# R7FA6T2BD register map
Vendor: Renesas Electronics Corporation; Series: RA6; File version: 1.40.00
CPU: CM33 r0p4, little endian, MPU, FPU, VTOR, 4 interrupt priority bits, 96 interrupts
Registers are 32-bit, read-write, reset 0x0 unless marked. A register's access mark holds for its fields unless they carry their own. Offsets are from the block's base; [hi:lo] are bit positions; {n}, {i} and the like mark numbered series.

## GPT320 — General PWM 32-bit Timer 0
Base 0x40169000
Same registers: GPT321 0x40169100, GPT322 0x40169200, GPT323 0x40169300
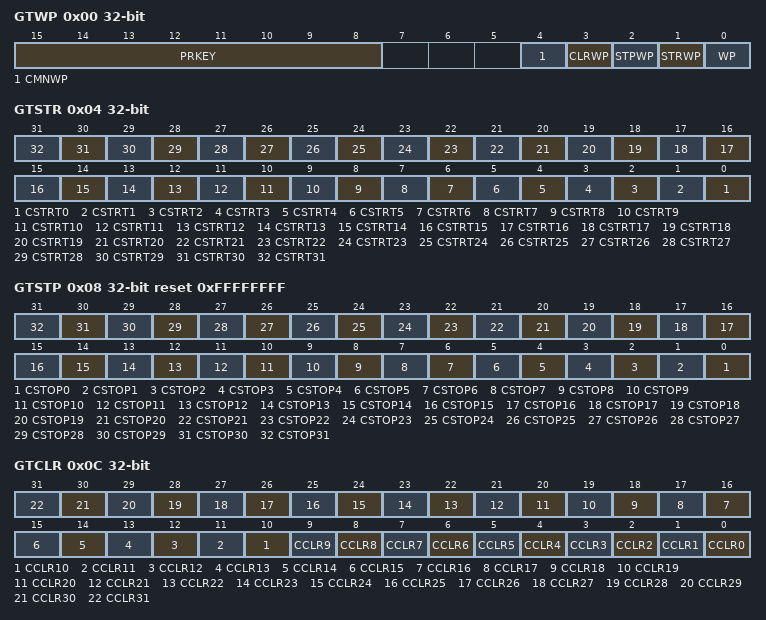
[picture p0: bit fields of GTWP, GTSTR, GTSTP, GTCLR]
0x00 GTWP — General PWM Timer Write,Protection Register
  [15:8] PRKEY wo — GTWP Key Code
  [4] CMNWP — Common Register Write Disabled
  [3] CLRWP — GTCLR.CCLR Bit Write Disable
  [2] STPWP — GTSTP.CSTOP Bit Write Disable
  [1] STRWP — GTSTR.CSTRT Bit Write Disable
  [0] WP — Register Write Disable
0x04 GTSTR — General PWM Timer Software Start Register
  [n] CSTRT{n} (n=0..31) — Channel n GTCNT Count Start (n is the same as the bit position value)
0x08 GTSTP reset 0xFFFFFFFF — General PWM Timer Software Stop Register
  [n] CSTOP{n} (n=0..31) — Channel n GTCNT Count Stop (n is the same as the bit position value)
0x0C GTCLR wo — General PWM Timer Software Clear Register
  [n] CCLR{n} (n=0..31) — Channel n GTCNT Count Clear (n : the same as bit position value)
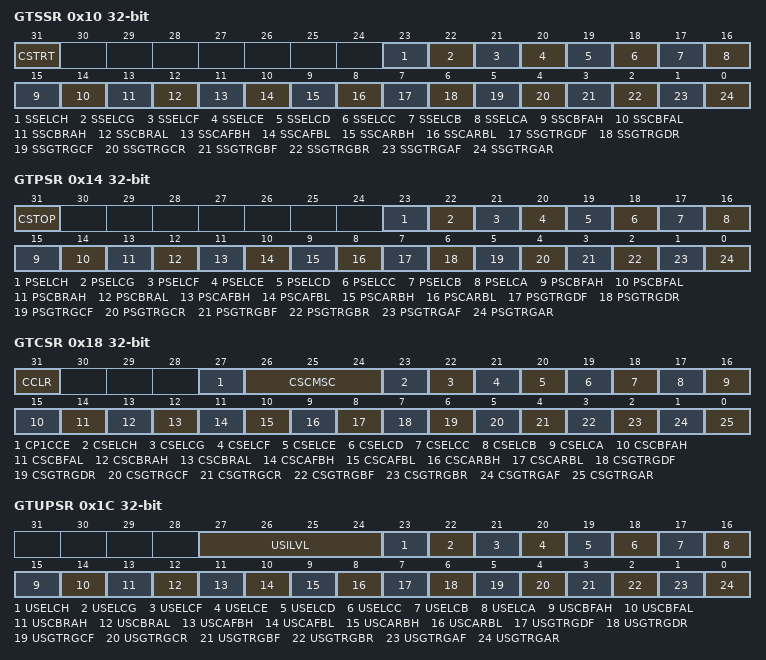
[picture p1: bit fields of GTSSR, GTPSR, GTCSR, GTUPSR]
0x10 GTSSR — General PWM Timer Start Source Select Register
  [31] CSTRT — Software Source Counter Start Enable
  [23] SSELCH — ELC_GPTH Event Source Counter Start Enable
  [22] SSELCG — ELC_GPTG Event Source Counter Start Enable
  [21] SSELCF — ELC_GPTF Event Source Counter Start Enable
  [20] SSELCE — ELC_GPTE Event Source Counter Start Enable
  [19] SSELCD — ELC_GPTD Event Source Counter Start Enable
  [18] SSELCC — ELC_GPTC Event Source Counter Start Enable
  [17] SSELCB — ELC_GPTB Event Source Counter Start Enable
  [16] SSELCA — ELC_GPTA Event Source Counter Start Enable
  [15] SSCBFAH — GTIOCnB Pin Falling Input during GTIOCnA Value High Source Counter Start Enable
  [14] SSCBFAL — GTIOCnB Pin Falling Input during GTIOCnA Value Low Source Counter Start Enable
  [13] SSCBRAH — GTIOCnB Pin Rising Input during GTIOCnA Value High Source Counter Start Enable
  [12] SSCBRAL — GTIOCnB Pin Rising Input during GTIOCnA Value Low Source Counter Start Enable
  [11] SSCAFBH — GTIOCnA Pin Falling Input during GTIOCnB Value High Source Counter Start Enable
  [10] SSCAFBL — GTIOCnA Pin Falling Input during GTIOCnB Value Low Source Counter Start Enable
  [9] SSCARBH — GTIOCnA Pin Rising Input during GTIOCnB Value High Source Counter Start Enable
  [8] SSCARBL — GTIOCnA Pin Rising Input during GTIOCnB Value Low Source Counter Start Enable
  [7] SSGTRGDF — GTETRGD Pin Falling Input Source Counter Start Enable
  [6] SSGTRGDR — GTETRGD Pin Rising Input Source Counter Start Enable
  [5] SSGTRGCF — GTETRGC Pin Falling Input Source Counter Start Enable
  [4] SSGTRGCR — GTETRGC Pin Rising Input Source Counter Start Enable
  [3] SSGTRGBF — GTETRGB Pin Falling Input Source Counter Start Enable
  [2] SSGTRGBR — GTETRGB Pin Rising Input Source Counter Start Enable
  [1] SSGTRGAF — GTETRGA Pin Falling Input Source Counter Start Enable
  [0] SSGTRGAR — GTETRGA Pin Rising Input Source Counter Start Enable
0x14 GTPSR — General PWM Timer Stop Source Select Register
  [31] CSTOP — Software Source Counter Stop Enable
  [23] PSELCH — ELC_GPTH Event Source Counter Stop Enable
  [22] PSELCG — ELC_GPTG Event Source Counter Stop Enable
  [21] PSELCF — ELC_GPTF Event Source Counter Stop Enable
  [20] PSELCE — ELC_GPTE Event Source Counter Stop Enable
  [19] PSELCD — ELC_GPTD Event Source Counter Stop Enable
  [18] PSELCC — ELC_GPTC Event Source Counter Stop Enable
  [17] PSELCB — ELC_GPTB Event Source Counter Stop Enable
  [16] PSELCA — ELC_GPTA Event Source Counter Stop Enable
  [15] PSCBFAH — GTIOCnB Pin Falling Input during GTIOCnA Value High Source Counter Stop Enable
  [14] PSCBFAL — GTIOCnB Pin Falling Input during GTIOCnA Value Low Source Counter Stop Enable
  [13] PSCBRAH — GTIOCnB Pin Rising Input during GTIOCnA Value High Source Counter Stop Enable
  [12] PSCBRAL — GTIOCnB Pin Rising Input during GTIOCnA Value Low Source Counter Stop Enable
  [11] PSCAFBH — GTIOCnA Pin Falling Input during GTIOCnB Value High Source Counter Stop Enable
  [10] PSCAFBL — GTIOCnA Pin Falling Input during GTIOCnB Value Low Source Counter Stop Enable
  [9] PSCARBH — GTIOCnA Pin Rising Input during GTIOCnB Value High Source Counter Stop Enable
  [8] PSCARBL — GTIOCnA Pin Rising Input during GTIOCnB Value Low Source Counter Stop Enable
  [7] PSGTRGDF — GTETRGD Pin Falling Input Source Counter Stop Enable
  [6] PSGTRGDR — GTETRGD Pin Rising Input Source Counter Stop Enable
  [5] PSGTRGCF — GTETRGC Pin Falling Input Source Counter Stop Enable
  [4] PSGTRGCR — GTETRGC Pin Rising Input Source Counter Stop Enable
  [3] PSGTRGBF — GTETRGB Pin Falling Input Source Counter Stop Enable
  [2] PSGTRGBR — GTETRGB Pin Rising Input Source Counter Stop Enable
  [1] PSGTRGAF — GTETRGA Pin Falling Input Source Counter Stop Enable
  [0] PSGTRGAR — GTETRGA Pin Rising Input Source Counter Stop Enable
0x18 GTCSR — General PWM Timer Clear Source Select Register
  [31] CCLR — Software Source Counter Clear Enable
  [27] CP1CCE — Complementary PWM mode1 Crest Source Counter Clear Enable
  [26:24] CSCMSC — Compare Match/Input Capture/Synchronous counter clearing Source Counter Clear Enable
  [23] CSELCH — ELC_GPTH Event Source Counter Clear Enable
  [22] CSELCG — ELC_GPTG Event Source Counter Clear Enable
  [21] CSELCF — ELC_GPTF Event Source Counter Clear Enable
  [20] CSELCE — ELC_GPTE Event Source Counter Clear Enable
  [19] CSELCD — ELC_GPTD Event Source Counter Clear Enable
  [18] CSELCC — ELC_GPTC Event Source Counter Clear Enable
  [17] CSELCB — ELC_GPTB Event Source Counter Clear Enable
  [16] CSELCA — ELC_GPTA Event Source Counter Clear Enable
  [15] CSCBFAH — GTIOCnB Pin Falling Input during GTIOCnA Value High Source Counter Clear Enable
  [14] CSCBFAL — GTIOCnB Pin Falling Input during GTIOCnA Value Low Source Counter Clear Enable
  [13] CSCBRAH — GTIOCnB Pin Rising Input during GTIOCnA Value High Source Counter Clear Enable
  [12] CSCBRAL — GTIOCnB Pin Rising Input during GTIOCnA Value Low Source Counter Clear Enable
  [11] CSCAFBH — GTIOCnA Pin Falling Input during GTIOCnB Value High Source Counter Clear Enable
  [10] CSCAFBL — GTIOCnA Pin Falling Input during GTIOCnB Value Low Source Counter Clear Enable
  [9] CSCARBH — GTIOCnA Pin Rising Input during GTIOCnB Value High Source Counter Clear Enable
  [8] CSCARBL — GTIOCnA Pin Rising Input during GTIOCnB Value Low Source Counter Clear Enable
  [7] CSGTRGDF — GTETRGD Pin Falling Input Source Counter Clear Enable
  [6] CSGTRGDR — GTETRGD Pin Rising Input Source Counter Clear Enable
  [5] CSGTRGCF — GTETRGC Pin Falling Input Source Counter Clear Enable
  [4] CSGTRGCR — GTETRGC Pin Rising Input Source Counter Clear Enable
  [3] CSGTRGBF — GTETRGB Pin Falling Input Source Counter Clear Enable
  [2] CSGTRGBR — GTETRGB Pin Rising Input Source Counter Clear Enable
  [1] CSGTRGAF — GTETRGA Pin Falling Input Source Counter Clear Enable
  [0] CSGTRGAR — GTETRGA Pin Rising Input Source Counter Clear Enable
0x1C GTUPSR — General PWM Timer Up Count Source Select Register
  [27:24] USILVL — External Input Level Source Count,Up Enable
  [23] USELCH — ELC_GPTH Event Source Counter Count Up Enable
  [22] USELCG — ELC_GPTG Event Source Counter Count Up Enable
  [21] USELCF — ELC_GPTF Event Source Counter Count Up Enable
  [20] USELCE — ELC_GPTE Event Source Counter Count Up Enable
  [19] USELCD — ELC_GPTD Event Source Counter Count Up Enable
  [18] USELCC — ELC_GPTC Event Source Counter Count Up Enable
  [17] USELCB — ELC_GPTB Event Source Counter Count Up Enable
  [16] USELCA — ELC_GPTA Event Source Counter Count Up Enable
  [15] USCBFAH — GTIOCnB Pin Falling Input during GTIOCnA Value High Source Counter Count Up Enable
  [14] USCBFAL — GTIOCnB Pin Falling Input during GTIOCnA Value Low Source Counter Count Up Enable
  [13] USCBRAH — GTIOCnB Pin Rising Input during GTIOCnA Value High Source Counter Count Up Enable
  [12] USCBRAL — GTIOCnB Pin Rising Input during GTIOCnA Value Low Source Counter Count Up Enable
  [11] USCAFBH — GTIOCnA Pin Falling Input during GTIOCnB Value High Source Counter Count Up Enable
  [10] USCAFBL — GTIOCnA Pin Falling Input during GTIOCnB Value Low Source Counter Count Up Enable
  [9] USCARBH — GTIOCnA Pin Rising Input during GTIOCnB Value High Source Counter Count Up Enable
  [8] USCARBL — GTIOCnA Pin Rising Input during GTIOCnB Value Low Source Counter Count Up Enable
  [7] USGTRGDF — GTETRGD Pin Falling Input Source Counter Count Up Enable
  [6] USGTRGDR — GTETRGD Pin Rising Input Source Counter Count Up Enable
  [5] USGTRGCF — GTETRGC Pin Falling Input Source Counter Count Up Enable
  [4] USGTRGCR — GTETRGC Pin Rising Input Source Counter Count Up Enable
  [3] USGTRGBF — GTETRGB Pin Falling Input Source Counter Count Up Enable
  [2] USGTRGBR — GTETRGB Pin Rising Input Source Counter Count Up Enable
  [1] USGTRGAF — GTETRGA Pin Falling Input Source Counter Count Up Enable
  [0] USGTRGAR — GTETRGA Pin Rising Input Source Counter Count Up Enable
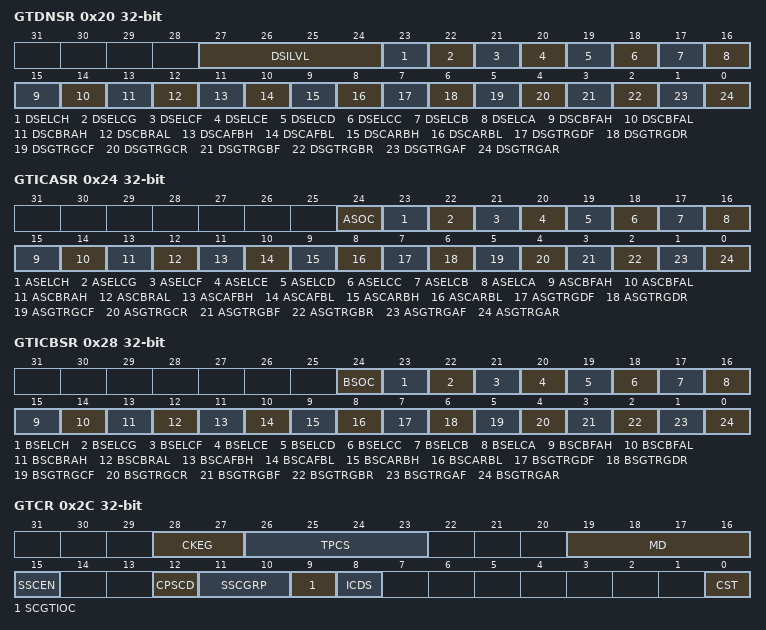
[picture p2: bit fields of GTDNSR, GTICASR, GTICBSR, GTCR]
0x20 GTDNSR — General PWM Timer Down Count Source Select Register
  [27:24] DSILVL — External Input Level Source Count,Down Enable
  [23] DSELCH — ELC_GPTF Event Source Counter Count Down Enable
  [22] DSELCG — ELC_GPTG Event Source Counter Count Down Enable
  [21] DSELCF — ELC_GPTF Event Source Counter Count Down Enable
  [20] DSELCE — ELC_GPTE Event Source Counter Count Down Enable
  [19] DSELCD — ELC_GPTD Event Source Counter Count Down Enable
  [18] DSELCC — ELC_GPTC Event Source Counter Count Down Enable
  [17] DSELCB — ELC_GPTB Event Source Counter Count Down Enable
  [16] DSELCA — ELC_GPTA Event Source Counter Count Down Enable
  [15] DSCBFAH — GTIOCnB Pin Falling Input during GTIOCnA Value High Source Counter Count Down Enable
  [14] DSCBFAL — GTIOCnB Pin Falling Input during GTIOCnA Value Low Source Counter Count Down Enable
  [13] DSCBRAH — GTIOCnB Pin Rising Input during GTIOCnA Value High Source Counter Count Down Enable
  [12] DSCBRAL — GTIOCnB Pin Rising Input during GTIOCnA Value Low Source Counter Count Down Enable
  [11] DSCAFBH — GTIOCnA Pin Falling Input during GTIOCnB Value High Source Counter Count Down Enable
  [10] DSCAFBL — GTIOCnA Pin Falling Input during GTIOCnB Value Low Source Counter Count Down Enable
  [9] DSCARBH — GTIOCnA Pin Rising Input during GTIOCnB Value High Source Counter Count Down Enable
  [8] DSCARBL — GTIOCnA Pin Rising Input during GTIOCnB Value Low Source Counter Count Down Enable
  [7] DSGTRGDF — GTETRGD Pin Falling Input Source Counter Count Down Enable
  [6] DSGTRGDR — GTETRGD Pin Rising Input Source Counter Count Down Enable
  [5] DSGTRGCF — GTETRGC Pin Falling Input Source Counter Count Down Enable
  [4] DSGTRGCR — GTETRGC Pin Rising Input Source Counter Count Down Enable
  [3] DSGTRGBF — GTETRGB Pin Falling Input Source Counter Count Down Enable
  [2] DSGTRGBR — GTETRGB Pin Rising Input Source Counter Count Down Enable
  [1] DSGTRGAF — GTETRGA Pin Falling Input Source Counter Count Down Enable
  [0] DSGTRGAR — GTETRGA Pin Rising Input Source Counter Count Down Enable
0x24 GTICASR — General PWM Timer Input Capture Source Select Register A
  [24] ASOC — Other channel Source GTCCRA Input Capture Enable
  [23] ASELCH — ELC_GPTH Event Source GTCCRA Input Capture Enable
  [22] ASELCG — ELC_GPTG Event Source GTCCRA Input Capture Enable
  [21] ASELCF — ELC_GPTF Event Source GTCCRA Input Capture Enable
  [20] ASELCE — ELC_GPTE Event Source GTCCRA Input Capture Enable
  [19] ASELCD — ELC_GPTD Event Source GTCCRA Input Capture Enable
  [18] ASELCC — ELC_GPTC Event Source GTCCRA Input Capture Enable
  [17] ASELCB — ELC_GPTB Event Source GTCCRA Input Capture Enable
  [16] ASELCA — ELC_GPTA Event Source GTCCRA Input Capture Enable
  [15] ASCBFAH — GTIOCnB Pin Falling Input during GTIOCnA Value High Source GTCCRA Input Capture Enable
  [14] ASCBFAL — GTIOCnB Pin Falling Input during GTIOCnA Value Low Source GTCCRA Input Capture Enable
  [13] ASCBRAH — GTIOCnB Pin Rising Input during GTIOCnA Value High Source GTCCRA Input Capture Enable
  [12] ASCBRAL — GTIOCnB Pin Rising Input during GTIOCnA Value Low Source GTCCRA Input Capture Enable
  [11] ASCAFBH — GTIOCnA Pin Falling Input during GTIOCnB Value High Source GTCCRA Input Capture Enable
  [10] ASCAFBL — GTIOCnA Pin Falling Input during GTIOCnB Value Low Source GTCCRA Input Capture Enable
  [9] ASCARBH — GTIOCnA Pin Rising Input during GTIOCnB Value High Source GTCCRA Input Capture Enable
  [8] ASCARBL — GTIOCnA Pin Rising Input during GTIOCnB Value Low Source GTCCRA Input Capture Enable
  [7] ASGTRGDF — GTETRGD Pin Falling Input Source GTCCRA Input Capture Enable
  [6] ASGTRGDR — GTETRGD Pin Rising Input Source GTCCRA Input Capture Enable
  [5] ASGTRGCF — GTETRGC Pin Falling Input Source GTCCRA Input Capture Enable
  [4] ASGTRGCR — GTETRGC Pin Rising Input Source GTCCRA Input Capture Enable
  [3] ASGTRGBF — GTETRGB Pin Falling Input Source GTCCRA Input Capture Enable
  [2] ASGTRGBR — GTETRGB Pin Rising Input Source GTCCRA Input Capture Enable
  [1] ASGTRGAF — GTETRGA Pin Falling Input Source GTCCRA Input Capture Enable
  [0] ASGTRGAR — GTETRGA Pin Rising Input Source GTCCRA Input Capture Enable
0x28 GTICBSR — General PWM Timer Input Capture Source Select Register B
  [24] BSOC — Other channel Source GTCCRB Input Capture Enable
  [23] BSELCH — ELC_GPTH Event Source GTCCRB Input Capture Enable
  [22] BSELCG — ELC_GPTG Event Source GTCCRB Input Capture Enable
  [21] BSELCF — ELC_GPTF Event Source GTCCRB Input Capture Enable
  [20] BSELCE — ELC_GPTE Event Source GTCCRB Input Capture Enable
  [19] BSELCD — ELC_GPTD Event Source GTCCRB Input Capture Enable
  [18] BSELCC — ELC_GPTC Event Source GTCCRB Input Capture Enable
  [17] BSELCB — ELC_GPTB Event Source GTCCRB Input Capture Enable
  [16] BSELCA — ELC_GPTA Event Source GTCCRB Input Capture Enable
  [15] BSCBFAH — GTIOCnB Pin Falling Input during GTIOCnA Value High Source GTCCRB Input Capture Enable
  [14] BSCBFAL — GTIOCnB Pin Falling Input during GTIOCnA Value Low Source GTCCRB Input Capture Enable
  [13] BSCBRAH — GTIOCnB Pin Rising Input during GTIOCnA Value High Source GTCCRB Input Capture Enable
  [12] BSCBRAL — GTIOCnB Pin Rising Input during GTIOCnA Value Low Source GTCCRB Input Capture Enable
  [11] BSCAFBH — GTIOCnA Pin Falling Input during GTIOCnB Value High Source GTCCRB Input Capture Enable
  [10] BSCAFBL — GTIOCnA Pin Falling Input during GTIOCnB Value Low Source GTCCRB Input Capture Enable
  [9] BSCARBH — GTIOCnA Pin Rising Input during GTIOCnB Value High Source GTCCRB Input Capture Enable
  [8] BSCARBL — GTIOCnA Pin Rising Input during GTIOCnB Value Low Source GTCCRB Input Capture Enable
  [7] BSGTRGDF — GTETRGD Pin Falling Input Source GTCCRB Input Capture Enable
  [6] BSGTRGDR — GTETRGD Pin Rising Input Source GTCCRB Input Capture Enable
  [5] BSGTRGCF — GTETRGC Pin Falling Input Source GTCCRB Input Capture Enable
  [4] BSGTRGCR — GTETRGC Pin Rising Input Source GTCCRB Input Capture Enable
  [3] BSGTRGBF — GTETRGB Pin Falling Input Source GTCCRB Input Capture Enable
  [2] BSGTRGBR — GTETRGB Pin Rising Input Source GTCCRB Input Capture Enable
  [1] BSGTRGAF — GTETRGA Pin Falling Input Source GTCCRB Input Capture Enable
  [0] BSGTRGAR — GTETRGA Pin Rising Input Source GTCCRB Input Capture Enable
0x2C GTCR — General PWM Timer Control Register
  [28:27] CKEG — Clock Edge Select
  [26:23] TPCS — Timer Prescaler Select
  [19:16] MD — Mode Select
  [15] SSCEN — Synchronous Set/Clear Enable
  [12] CPSCD — Complementary PWM Mode Synchronous Clear Disable
  [11:10] SSCGRP — Synchronous Set/Clear Group Select
  [9] SCGTIOC — GTIOC input Source Synchronous Clear Enable
  [8] ICDS — Input Capture Operation Select During Count Stop
  [0] CST — Count Start
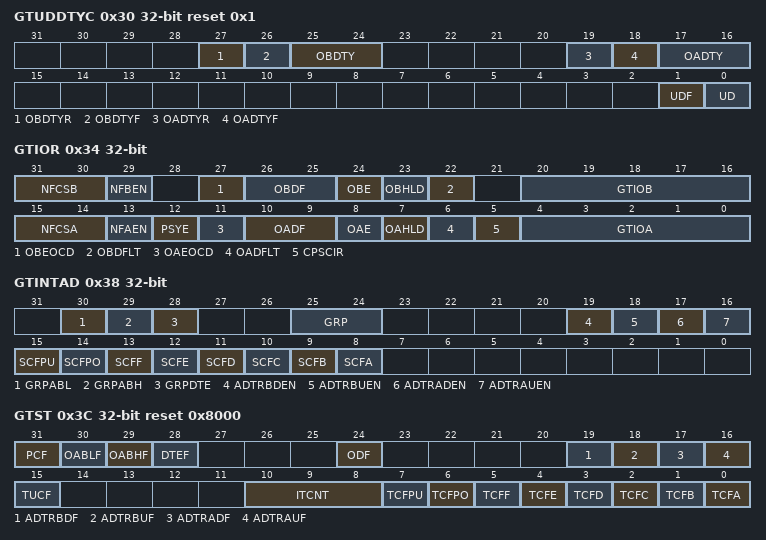
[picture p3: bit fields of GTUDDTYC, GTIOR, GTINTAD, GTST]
0x30 GTUDDTYC reset 0x1 — General PWM Timer Count Direction and Duty Setting Register
  [27] OBDTYR — GTIOCnB Output Value Selecting after Releasing 0%/100% Duty Setting
  [26] OBDTYF — Forcible GTIOCnB Output Duty Setting
  [25:24] OBDTY — GTIOCnB Output Duty Setting
  [19] OADTYR — GTIOCnA Output Value Selecting after Releasing 0%/100% Duty Setting
  [18] OADTYF — Forcible GTIOCnA Output Duty Setting
  [17:16] OADTY — GTIOCnA Output Duty Setting
  [1] UDF — Forcible Count Direction Setting
  [0] UD — Count Direction Setting
0x34 GTIOR — General PWM Timer I/O Control Register
  [31:30] NFCSB — Noise Filter B Sampling Clock Select
  [29] NFBEN — Noise Filter B Enable
  [27] OBEOCD — GTCCRB Compare Match Cycle End Output Invalidate
  [26:25] OBDF — GTIOCnB Pin Disable Value Setting
  [24] OBE — GTIOCnB Pin Output Enable
  [23] OBHLD — GTIOCnB Pin Output Setting at the Start/Stop Count
  [22] OBDFLT — GTIOCnB Pin Output Value Setting at the Count Stop
  [20:16] GTIOB — GTIOCnB Pin Function Select
  [15:14] NFCSA — Noise Filter A Sampling Clock Select
  [13] NFAEN — Noise Filter A Enable
  [12] PSYE — PWM Synchronous output Enable
  [11] OAEOCD — GTCCRA Compare Match Cycle End Output Invalidate
  [10:9] OADF — GTIOCnA Pin Disable Value Setting
  [8] OAE — GTIOCnA Pin Output Enable
  [7] OAHLD — GTIOCnA Pin Output Setting at the Start/Stop Count
  [6] OADFLT — GTIOCnA Pin Output Value Setting at the Count Stop
  [5] CPSCIR — Complementary PWM Mode Initial Output at Synchronous Clear Disable
  [4:0] GTIOA — GTIOCnA Pin Function Select
0x38 GTINTAD — General PWM Timer Interrupt Output Setting Register
  [30] GRPABL — Same Time Output Level Low Disable Request Enable
  [29] GRPABH — Same Time Output Level High Disable Request Enable
  [28] GRPDTE — Dead Time Error Output Disable Request Enable
  [25:24] GRP — Output Disable Source Select
  [19] ADTRBDEN — GTADTRB Register Compare Match (Down,Counting) A/D Conversion Start Request Enable
  [18] ADTRBUEN — GTADTRB Register Compare Match (Up,Counting) A/D Conversion Start Request Enable
  [17] ADTRADEN — GTADTRA Register Compare Match (Down,Counting) A/D Conversion Start Request Enable
  [16] ADTRAUEN — GTADTRA Register Compare Match (Up,Counting) A/D Conversion Start Request Enable
  [15] SCFPU — Underflow Source Synchronous Clear Enable
  [14] SCFPO — Overflow Source Synchronous Clear Enable
  [13] SCFF — GTCCRF Register Compare Match Source Synchronous Clear Enable
  [12] SCFE — GTCCRE Register Compare Match Source Synchronous Clear Enable
  [11] SCFD — GTCCRD Register Compare Match Source Synchronous Clear Enable
  [10] SCFC — GTCCRC Register Compare Match Source Synchronous Clear Enable
  [9] SCFB — GTCCRB Register Compare Match/Input Capture Source Synchronous Clear Enable
  [8] SCFA — GTCCRA Register Compare Match/Input Capture Source Synchronous Clear Enable
0x3C GTST reset 0x8000 — General PWM Timer Status Register
  [31] PCF — Period Count Function Finish Flag
  [30] OABLF ro — Same Time Output Level Low Flag
  [29] OABHF ro — Same Time Output Level High Flag
  [28] DTEF ro — Dead Time Error Flag
  [24] ODF ro — Output Disable Flag
  [19] ADTRBDF — GTADTRB Register Compare Match (Down,Counting) A/D Conversion Start Request Flag
  [18] ADTRBUF — GTADTRB Register Compare Match (Up,Counting) A/D Conversion Start Request Flag
  [17] ADTRADF — GTADTRA Register Compare Match (Down,Counting) A/D Conversion Start Request Flag
  [16] ADTRAUF — GTADTRA Register Compare Match (Up,Counting) A/D Conversion Start Request Flag
  [15] TUCF ro — Count Direction Flag
  [10:8] ITCNT ro — GPTn_OVF/GPTn_UDF Interrupt Skipping Count Counter
  [7] TCFPU — Underflow Flag
  [6] TCFPO — Overflow Flag
  [5] TCFF — Input Compare Match Flag F
  [4] TCFE — Input Compare Match Flag E
  [3] TCFD — Input Compare Match Flag D
  [2] TCFC — Input Compare Match Flag C
  [1] TCFB — Input Capture/Compare Match Flag B
  [0] TCFA — Input Capture/Compare Match Flag A
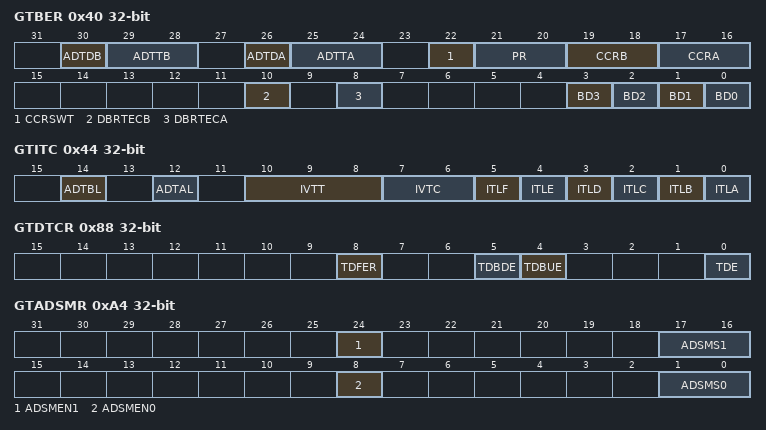
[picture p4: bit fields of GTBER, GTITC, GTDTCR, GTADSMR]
0x40 GTBER — General PWM Timer Buffer Enable Register
  [30] ADTDB — GTADTRB Register Double Buffer Operation
  [29:28] ADTTB — GTADTRB Register Buffer Transfer Timing Select
  [26] ADTDA — GTADTRA Register Double Buffer Operation
  [25:24] ADTTA — GTADTRA Register Buffer Transfer Timing Select
  [22] CCRSWT wo — GTCCRA and GTCCRB Forcible Buffer Operation
  [21:20] PR — GTPR Buffer Operation
  [19:18] CCRB — GTCCRB Buffer Operation
  [17:16] CCRA — GTCCRA Buffer Operation
  [10] DBRTECB — GTCCRB Register Double Buffer Repeat Operation Enable
  [8] DBRTECA — GTCCRA Register Double Buffer Repeat Operation Enable
  [3] BD3 — GTDVU/GTDVD Registers Buffer Operation Disable
  [2] BD2 — GTADTRA/GTADTRB Registers Buffer Operation Disable
  [1] BD1 — GTPR Buffer Operation Disable
  [0] BD0 — GTCCR Buffer Operation Disable
0x44 GTITC — General PWM Timer Interrupt and A/D Conversion Start Request Skipping Setting Register
  [14] ADTBL — GTADTRB Register A/D Conversion Start Request Link
  [12] ADTAL — GTADTRA Register A/D Conversion Start Request Link
  [10:8] IVTT — GPTn_OVF/GPTn_UDF Interrupt Skipping Count Select
  [7:6] IVTC — GPTn_OVF/GPTn_UDF Interrupt Skipping Function Select
  [5] ITLF — GTCCRF Register Compare Match Interrupt Link
  [4] ITLE — GTCCRE Register Compare Match Interrupt Link
  [3] ITLD — GTCCRD Register Compare Match Interrupt Link
  [2] ITLC — GTCCRC Register Compare Match Interrupt Link
  [1] ITLB — GTCCRB Register Compare Match/Input Capture Interrupt Link
  [0] ITLA — GTCCRA Register Compare Match/Input Capture Interrupt Link
0x48 GTCNT — General PWM Timer Counter
0x4C GTCCRA reset 0xFFFFFFFF — General PWM Timer Compare Capture Register A
0x50 GTCCRB reset 0xFFFFFFFF — General PWM Timer Compare Capture Register B
0x54 GTCCRC reset 0xFFFFFFFF — General PWM Timer Compare Capture Register C
0x58 GTCCRE reset 0xFFFFFFFF — General PWM Timer Compare Capture Register E
0x5C GTCCRD reset 0xFFFFFFFF — General PWM Timer Compare Capture Register D
0x60 GTCCRF reset 0xFFFFFFFF — General PWM Timer Compare Capture Register F
0x64 GTPR reset 0xFFFFFFFF — General PWM Timer Cycle Setting Register
0x68 GTPBR reset 0xFFFFFFFF — General PWM Timer Cycle Setting Buffer Register
0x6C GTPDBR reset 0xFFFFFFFF — General PWM Timer Cycle Setting Double,Buffer Register
0x70 GTADTRA reset 0xFFFFFFFF — A/D Conversion Start Request Timing Register A
0x74 GTADTBRA reset 0xFFFFFFFF — A/D Conversion Start Request Timing Buffer Register A
0x78 GTADTDBRA reset 0xFFFFFFFF — A/D Conversion Start Request Timing Double,Buffer Register A
0x7C GTADTRB reset 0xFFFFFFFF — A/D Conversion Start Request Timing Register B
0x80 GTADTBRB reset 0xFFFFFFFF — A/D Conversion Start Request Timing Buffer Register B
0x84 GTADTDBRB reset 0xFFFFFFFF — A/D Conversion Start Request Timing Double,Buffer Register B
0x88 GTDTCR — General PWM Timer Dead Time Control Register
  [8] TDFER — GTDVD Register Setting
  [5] TDBDE — GTDVD Register Buffer Operation Enable
  [4] TDBUE — GTDVU Register Buffer Operation Enable
  [0] TDE — Negative,Phase Waveform Setting
0x8C GTDVU reset 0xFFFFFFFF — General PWM Timer Dead Time Value Register U
0x90 GTDVD reset 0xFFFFFFFF — General PWM Timer Dead Time Value Register D
0x94 GTDBU reset 0xFFFFFFFF — General PWM Timer Dead Time Buffer Register U
0x98 GTDBD reset 0xFFFFFFFF — General PWM Timer Dead Time Buffer Register D
0x9C GTSOS ro — General PWM Timer Output Protection Function Status Register
  [1:0] SOS — Output Protection Function Status
0xA0 GTSOTR — General PWM Timer Output Protection Function Temporary Release Register
  [0] SOTR — Output Protection Function Temporary Release
0xA4 GTADSMR — General PWM Timer A/D Conversion Start Request Signal Monitoring Register
  [24] ADSMEN1 — A/D Conversion Start Request Signal Monitor 1 Output Enabling
  [17:16] ADSMS1 — A/D Conversion Start Request Signal Monitor 1 Selection
  [8] ADSMEN0 — A/D Conversion Start Request Signal Monitor 0 Output Enabling
  [1:0] ADSMS0 — A/D Conversion Start Request Signal Monitor 0 Selection
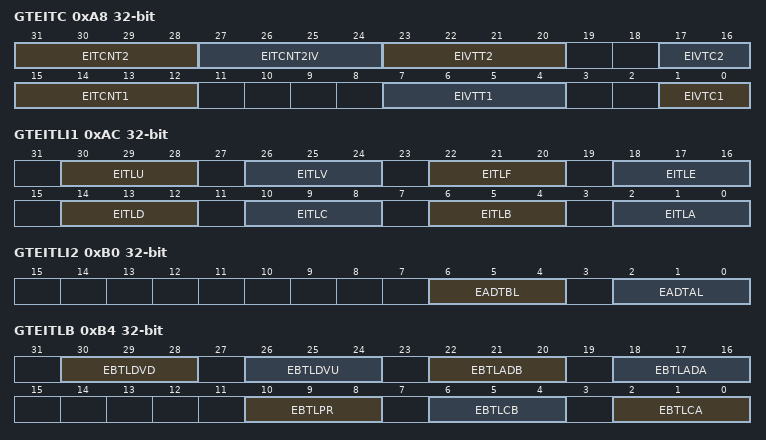
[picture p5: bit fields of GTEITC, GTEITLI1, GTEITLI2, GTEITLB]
0xA8 GTEITC — General PWM Timer Extended Interrupt Skipping Counter Control Register
  [31:28] EITCNT2 ro — Extended Interrupt Skipping Counter 2
  [27:24] EITCNT2IV — Extended Interrupt Skipping Counter 2 Initial Value
  [23:20] EIVTT2 — Extended Interrupt Skipping 2 Skipping Count Setting
  [17:16] EIVTC2 — Extended Interrupt Skipping Counter 2 Count Source select
  [15:12] EITCNT1 ro — Extended Interrupt Skipping Counter 1
  [7:4] EIVTT1 — Extended Interrupt Skipping 1 Skipping Count Setting
  [1:0] EIVTC1 — Extended Interrupt Skipping Counter 1 Count Source Select
0xAC GTEITLI1 — General PWM Timer Extended Interrupt Skipping Setting Register 1
  [30:28] EITLU — Underflow Interrupt Extended Skipping Function Select
  [26:24] EITLV — Overflow Interrupt Extended Skipping Function Select
  [22:20] EITLF — GTCCRF Register Compare Match Interrupt Extended Skipping Function Select
  [18:16] EITLE — GTCCRE Register Compare Match Interrupt Extended Skipping Function Select
  [14:12] EITLD — GTCCRD Register Compare Match Interrupt Extended Skipping Function Select
  [10:8] EITLC — GTCCRC Register Compare Match Interrupt Extended Skipping Function Select
  [6:4] EITLB — GTCCRB Register Compare Match/Input Capture Interrupt Extended Skipping Function Select
  [2:0] EITLA — GTCCRA Register Compare Match/Input Capture Interrupt Extended Skipping Function Select
0xB0 GTEITLI2 — General PWM Timer Extended Interrupt Skipping Setting Register 2
  [6:4] EADTBL — GTADTRB Register A/D Conversion Start Request Extended Skipping Function Select
  [2:0] EADTAL — GTADTRA Register A/D Conversion Start Request Extended Skipping Function Select
0xB4 GTEITLB — General PWM Timer Extended Buffer Transfer Skipping Setting Register
  [30:28] EBTLDVD — GTDVD Register Buffer Transfer Extended Skipping Function Select
  [26:24] EBTLDVU — GTDVU Register Buffer Transfer Extended Skipping Function Select
  [22:20] EBTLADB — GTADTRB Register Buffer Transfer Extended Skipping Function Select
  [18:16] EBTLADA — GTADTRA Register Buffer Transfer Extended Skipping Function Select
  [10:8] EBTLPR — GTPR Register Buffer Transfer Extended Skipping Function Select
  [6:4] EBTLCB — GTCCRB Register Buffer Transfer Extended Skipping Function Select
  [2:0] EBTLCA — GTCCRA Register Buffer Transfer Extended Skipping Function Select
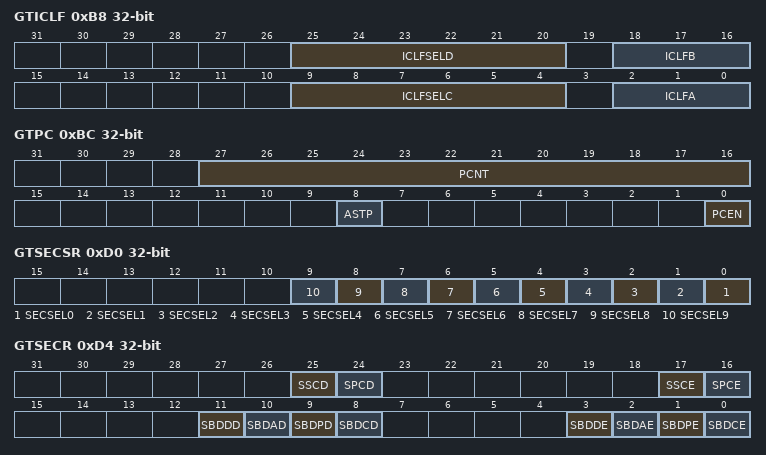
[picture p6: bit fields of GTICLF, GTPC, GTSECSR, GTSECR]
0xB8 GTICLF — General PWM Timer Inter Channel Logical Operation Function Setting Register
  [25:20] ICLFSELD — Inter Channel Signal D Select
  [18:16] ICLFB — GTIOCnB Output Logical Operation Function Select
  [9:4] ICLFSELC — Inter Channel Signal C Select
  [2:0] ICLFA — GTIOCnA Output Logical Operation Function Select
0xBC GTPC — General PWM Timer Period Count Register
  [27:16] PCNT — Period Counter
  [8] ASTP — Automatic Stop Function Enable
  [0] PCEN — Period Count Function Enable
0xD0 GTSECSR — General PWM Timer Operation Enable Bit Simultaneous Control Channel Select Register
  [n] SECSEL{n} (n=0..9) — Channel {n} Operation Enable Bit Simultaneous Control Channel Select
0xD4 GTSECR — General PWM Timer Operation Enable Bit Simultaneous Control Register
  [25] SSCD — Synchronous Set/Clear Simultaneous Disable
  [24] SPCD — Period Count Function Simultaneous Disable
  [17] SSCE — Synchronous Set/Clear Simultaneous Enable
  [16] SPCE — Period Count Function Simultaneous Enable
  [11] SBDDD — GTDV Register Buffer Operation Simultaneous Disable
  [10] SBDAD — GTADTR Register Buffer Operation Simultaneous Disable
  [9] SBDPD — GTPR Register Buffer Operation Simultaneous Disable
  [8] SBDCD — GTCCR Register Buffer Operation Simultaneous Disable
  [3] SBDDE — GTDV Register Buffer Operation Simultaneous Enable
  [2] SBDAE — GTADTR Register Buffer Operation Simultaneous Enable
  [1] SBDPE — GTPR Register Buffer Operation Simultaneous Enable
  [0] SBDCE — GTCCR Register Buffer Operation Simultaneous Enable
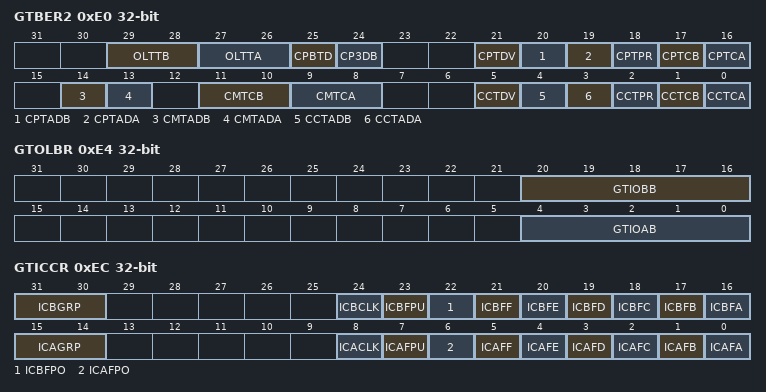
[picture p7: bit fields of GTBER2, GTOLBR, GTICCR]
0xE0 GTBER2 — General PWM Timer Buffer Enable Register 2
  [29:28] OLTTB — GTIOCnB Output Level Buffer Transfer Timing Select
  [27:26] OLTTA — GTIOCnA Output Level Buffer Transfer Timing Select
  [25] CPBTD — Complementary PWM mode Buffer Transfer Disable
  [24] CP3DB — Complementary PWM mode 3,4 Double Buffer select
  [21] CPTDV — Overflow/Underflow Source GTDVU/GTDVD Register Buffer Transfer Disable
  [20] CPTADB — Overflow/Underflow Source GTADTRB Register Buffer Transfer Disable
  [19] CPTADA — Overflow/Underflow Source GTADTRA Register Buffer Transfer Disable
  [18] CPTPR — Overflow/Underflow Source GTPR Register Buffer Transfer Disable
  [17] CPTCB — Overflow/Underflow Source GTCCRB Register Buffer Transfer Disable
  [16] CPTCA — Overflow/Underflow Source GTCCRA Register Buffer Transfer Disable
  [14] CMTADB — Compare Match Source GTADTRB Register Buffer Transfer Enable
  [13] CMTADA — Compare Match Source GTADTRA Register Buffer Transfer Enable
  [11:10] CMTCB — Compare Match Source GTCCRB Register Buffer Transfer Enable
  [9:8] CMTCA — Compare Match Source GTCCRA Register Buffer Transfer Enable
  [5] CCTDV — Counter Clear Source GTDVU/GTDVD Register Buffer Transfer Disable
  [4] CCTADB — Counter Clear Source GTADTRB Register Buffer Transfer Disable
  [3] CCTADA — Counter Clear Source GTADTRA Register Buffer Transfer Disable
  [2] CCTPR — Counter Clear Source GTPR Register Buffer Transfer Disable
  [1] CCTCB — Counter Clear Source GTCCRB Register Buffer Transfer Disable
  [0] CCTCA — Counter Clear Source GTCCRA Register Buffer Transfer Disable
0xE4 GTOLBR — General PWM Timer Output Level Buffer Register
  [20:16] GTIOBB — GTIOB buffer bits
  [4:0] GTIOAB — GTIOA buffer bits
0xEC GTICCR — General PWM Timer Inter Channel Cooperation Input Capture Control Register
  [31:30] ICBGRP — GTCCRB Input Capture Group Select
  [24] ICBCLK — Forwarding Count Clock to Other Channel GTCCRB Input Capture Source Enable
  [23] ICBFPU — Forwarding Underflow to Other Channel GTCCRB Input Capture Source Enable
  [22] ICBFPO — Forwarding Overflow to Other Channel GTCCRB Input Capture Source Enable
  [21] ICBFF — Forwarding GTCCRF register Compare Match to Other Channel GTCCRB Input Capture Source Enable
  [20] ICBFE — Forwarding GTCCRE register Compare Match to Other Channel GTCCRB Input Capture Source Enable
  [19] ICBFD — Forwarding GTCCRD register Compare Match to Other Channel GTCCRB Input Capture Source Enable
  [18] ICBFC — Forwarding GTCCRC register Compare Match to Other Channel GTCCRB Input Source Capture Enable
  [17] ICBFB — Forwarding GTCCRB register Compare Match/Input Capture to Other Channel GTCCRB Input Capture Source Enable
  [16] ICBFA — Forwarding GTCCRA register Compare Match/Input Capture to Other Channel GTCCRB Input Capture Source Enable
  [15:14] ICAGRP — GTCCRA Input Capture Group Select
  [8] ICACLK — Forwarding Count Clock to Other Channel GTCCRA Input Capture Source Enable
  [7] ICAFPU — Forwarding Underflow to Other Channel GTCCRA Input Capture Source Enable
  [6] ICAFPO — Forwarding Overflow to Other Channel GTCCRA Input Capture Source Enable
  [5] ICAFF — Forwarding GTCCRF register Compare Match to Other Channel GTCCRA Input Capture Source Enable
  [4] ICAFE — Forwarding GTCCRE register Compare Match to Other Channel GTCCRA Input Capture Source Enable
  [3] ICAFD — Forwarding GTCCRD register Compare Match to Other Channel GTCCRA Input Capture Source Enable
  [2] ICAFC — Forwarding GTCCRC register Compare Match to Other Channel GTCCRA Input Source Capture Enable
  [1] ICAFB — Forwarding GTCCRB register Compare Match/Input Capture to Other Channel GTCCRA Input Capture Source Enable
  [0] ICAFA — Forwarding GTCCRA register Compare Match/Input Capture to Other Channel GTCCRA Input Capture Source Enable

## GPT324 — General PWM 32-bit Timer 4
Base 0x40169400
Same registers: GPT325 0x40169500, GPT326 0x40169600, GPT327 0x40169700, GPT328 0x40169800, GPT329 0x40169900
Registers as GPT320, without GTUPSR, GTDNSR, GTPC; these are added or differ:
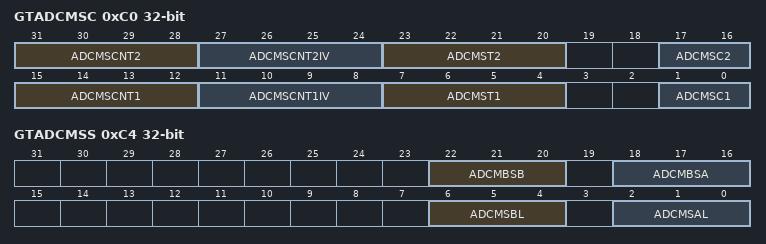
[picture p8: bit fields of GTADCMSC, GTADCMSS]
0xC0 GTADCMSC — General PWM Timer A/D Conversion Start Request Compare Match Skipping Control Register
  [31:28] ADCMSCNT2 ro — A/D Conversion Start Request Compare Match Skipping Counter 2
  [27:24] ADCMSCNT2IV — A/D Conversion Start Request Compare Match Skipping Counter 2 Initial Value
  [23:20] ADCMST2 — A/D Conversion Start Request Compare Match Skipping 2 Skipping Count Setting
  [17:16] ADCMSC2 — A/D Conversion Start Request Compare Match Skipping Counter 2 Count Source Select
  [15:12] ADCMSCNT1 ro — A/D Conversion Start Request Compare Match Skipping Counter 1
  [11:8] ADCMSCNT1IV — A/D Conversion Start Request Compare Match Skipping Counter 1 Initial Value
  [7:4] ADCMST1 — A/D Conversion Start Request Compare Match Skipping 1 Skipping Count Setting
  [1:0] ADCMSC1 — A/D Conversion Start Request Compare Match Skipping Counter 1 Count Source Select
0xC4 GTADCMSS — General PWM Timer A/D Conversion Start Request Compare Match Skipping Setting Register
  [22:20] ADCMBSB — GTADTRB Register Buffer Transfer by A/D Conversion Start Request Compare Match Skipping Function Select
  [18:16] ADCMBSA — GTADTRA Register Buffer Transfer by A/D Conversion Start Request Compare Match Skipping Function Select
  [6:4] ADCMSBL — GTADTRB Register A/D Conversion Start Request Compare Match Skipping Function Select
  [2:0] ADCMSAL — GTADTRA Register A/D Conversion Start Request Compare Match Skipping Function Select
